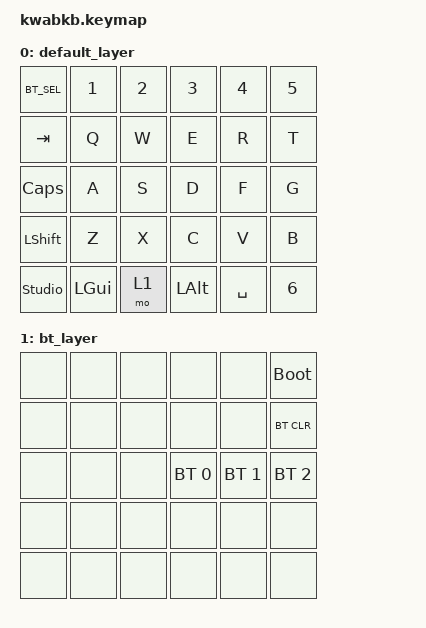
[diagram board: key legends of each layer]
#include <behaviors.dtsi>
#include <dt-bindings/zmk/keys.h>
#include <dt-bindings/zmk/bt.h>

/ {
   keymap {
       compatible = "zmk,keymap";
        default_layer {
          bindings = <
          &kp BT_SEL 0        &kp N1        &kp N2		&kp N3		    &kp N4		    &kp N5
          &kp TAB        &kp Q         &kp W		&kp E		    &kp R		    &kp T
          &kp CAPS       &kp A         &kp S		&kp D		    &kp F		    &kp G
		  &kp LSHIFT     &kp Z         &kp X		&kp C		    &kp V		    &kp B
		  &studio_unlock      &kp LGUI      &mo 1		&kp LALT		&kp SPACE		&kp N6
          >;
      };

      bt_layer {
          bindings = <
          &none        &none        &none        &none        &none        &bootloader
          &none        &none        &none        &none        &none        &bt BT_CLR
          &none        &none        &none        &bt BT_SEL 0 &bt BT_SEL 1 &bt BT_SEL 2
		  &none        &none        &none        &none        &none        &none        
		  &none        &none        &none        &none        &none        &none        
          >;
      };
  };
};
